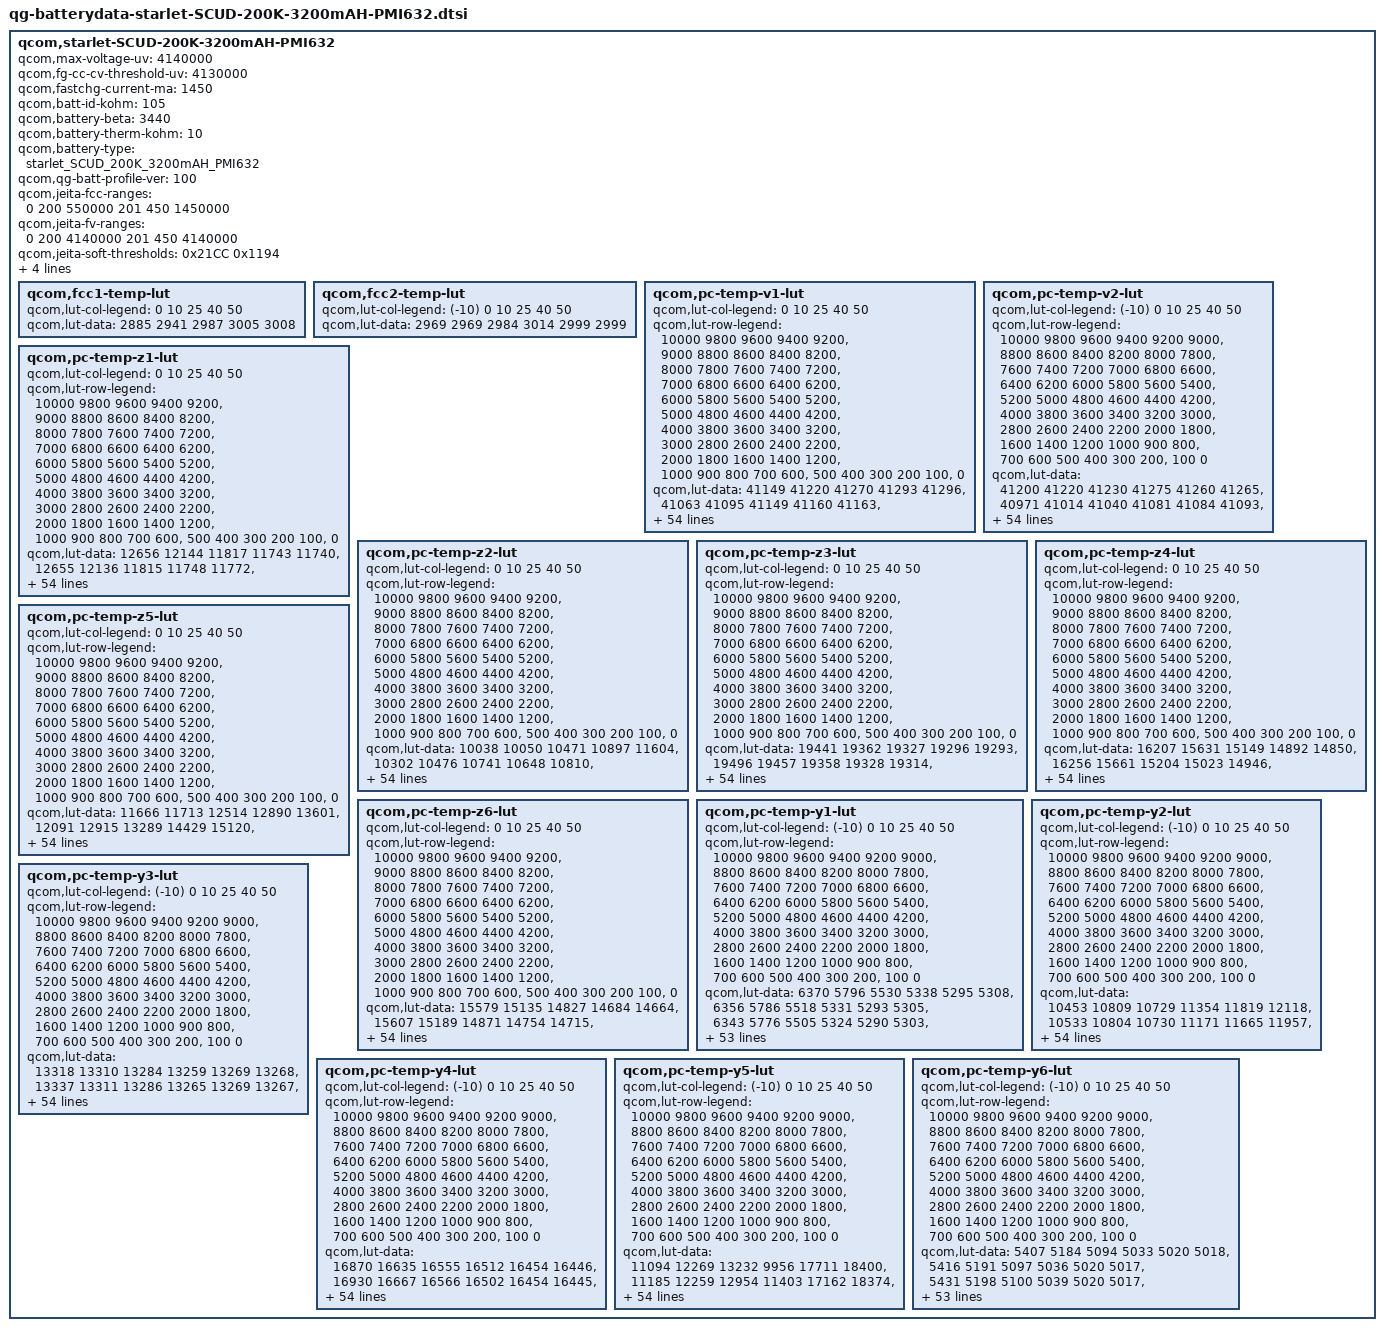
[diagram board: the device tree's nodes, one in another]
qcom,starlet-SCUD-200K-3200mAH-PMI632 {
	qcom,max-voltage-uv = <4140000>;
	qcom,fg-cc-cv-threshold-uv = <4130000>;
	qcom,fastchg-current-ma = <1450>;
	qcom,batt-id-kohm = <105>; // 220K on board in parallel with 200K on pack = 104.76K
	qcom,battery-beta = <3440>;
	qcom,battery-therm-kohm = <10>;
	qcom,battery-type = "starlet_SCUD_200K_3200mAH_PMI632";
	qcom,qg-batt-profile-ver = <100>;

	qcom,jeita-fcc-ranges = <0  200  550000
				201 450  1450000>;

	qcom,jeita-fv-ranges = <0   200  4140000
				201 450  4140000>;

	/*
	 * JEITA ADC values are calculated as follows, assuming
	 * a 30K pull-up. r_therm comes from the NTCG063JF103FTB
	 * thermistor datasheet.
	 *   v_adc = v_pull / ((r_pullup + r_therm) * r_therm)
	 *   v_adc = 1.875 / ((30K + r_therm) * r_therm)
	 *   adc_code = v_adc * v_fullscale / v_ref
	 *   adc_code = 10000 * v_adc * 2.89 / 1.875
	 *
	 * NOTE: to compensate for high IR drop with the starlet
	 * battery flex and connector, r_therm values are used
	 * that correspond roughly to 1.5C lower than the desired
	 * temperatures. Ie. the ADC under-reports temperatures,
	 * so we use lower thresholds to compensate.
	 */
	/* COOL = 20 degC, WARM = 43 degC */
	qcom,jeita-soft-thresholds = <0x21CC 0x1194>; /* 18.5 degC, 41.5 degC */
	/* COLD = 0 degC, HOT = 45 degC*/
	qcom,jeita-hard-thresholds = <0x379A 0x1096>; /* -1.5 degC, 43.5 degC */
	/* COOL hys = 23 degC, WARM hys = 42 degC */
	qcom,jeita-soft-hys-thresholds = <0x1F20 0x1218>; /* 21.5 degC, 40.5 degC */
	qcom,jeita-soft-fcc-ua = <550000 550000>;
	qcom,jeita-soft-fv-uv = <4140000 4140000>;


	qcom,fcc1-temp-lut {
		qcom,lut-col-legend = <0 10 25 40 50>;
		qcom,lut-data = <2885 2941 2987 3005 3008>;
	};

	qcom,fcc2-temp-lut {
		qcom,lut-col-legend = <(-10) 0 10 25 40 50>;
		qcom,lut-data = <2969 2969 2984 3014 2999 2999>;
	};

	qcom,pc-temp-v1-lut {
		qcom,lut-col-legend = <0 10 25 40 50>;
		qcom,lut-row-legend = <10000 9800 9600 9400 9200>,
			<9000 8800 8600 8400 8200>,
			<8000 7800 7600 7400 7200>,
			<7000 6800 6600 6400 6200>,
			<6000 5800 5600 5400 5200>,
			<5000 4800 4600 4400 4200>,
			<4000 3800 3600 3400 3200>,
			<3000 2800 2600 2400 2200>,
			<2000 1800 1600 1400 1200>,
			<1000 900 800 700 600>,
			<500 400 300 200 100>,
			<0>;
		qcom,lut-data = <41149 41220 41270 41293 41296>,
			<41063 41095 41149 41160 41163>,
			<41001 41013 41043 41058 41062>,
			<40945 40960 40974 40986 40990>,
			<40888 40911 40929 40939 40943>,
			<40833 40856 40877 40891 40897>,
			<40756 40792 40813 40825 40832>,
			<40616 40697 40729 40742 40752>,
			<40433 40533 40599 40624 40636>,
			<40239 40333 40405 40433 40442>,
			<40015 40121 40193 40214 40219>,
			<39803 39892 39968 39996 40003>,
			<39624 39691 39747 39772 39782>,
			<39460 39523 39568 39585 39595>,
			<39312 39372 39415 39428 39437>,
			<39184 39234 39273 39284 39291>,
			<39055 39109 39142 39148 39153>,
			<38912 38974 39011 39019 39021>,
			<38758 38823 38866 38876 38876>,
			<38594 38660 38709 38720 38720>,
			<38418 38483 38529 38542 38542>,
			<38229 38292 38310 38313 38318>,
			<38034 38074 38062 38050 38062>,
			<37830 37797 37794 37802 37820>,
			<37613 37497 37505 37560 37587>,
			<37366 37252 37268 37344 37375>,
			<37108 37043 37103 37170 37198>,
			<36902 36872 36965 37018 37040>,
			<36730 36743 36836 36878 36896>,
			<36588 36636 36718 36747 36763>,
			<36478 36535 36605 36625 36639>,
			<36389 36441 36491 36509 36521>,
			<36302 36348 36379 36397 36410>,
			<36216 36250 36272 36285 36297>,
			<36129 36147 36167 36175 36185>,
			<36033 36041 36059 36061 36067>,
			<35930 35933 35948 35942 35941>,
			<35814 35814 35829 35817 35806>,
			<35687 35673 35684 35668 35651>,
			<35543 35506 35509 35490 35474>,
			<35363 35315 35311 35289 35275>,
			<35126 35083 35082 35057 35041>,
			<34889 34840 34836 34807 34788>,
			<34662 34603 34588 34559 34541>,
			<34456 34391 34367 34336 34322>,
			<34299 34222 34184 34149 34140>,
			<34231 34152 34105 34066 34057>,
			<34166 34083 34030 33984 33975>,
			<34099 34011 33952 33900 33888>,
			<34008 33916 33852 33799 33780>,
			<33852 33735 33678 33585 33533>,
			<33503 33322 33283 33163 33107>,
			<32960 32755 32742 32623 32569>,
			<32273 32030 32047 31941 31890>,
			<31357 31048 31114 31025 30986>,
			<30000 30000 30000 30000 30000>;
	};

	qcom,pc-temp-v2-lut {
		qcom,lut-col-legend = <(-10) 0 10 25 40 50>;
		qcom,lut-row-legend = <10000 9800 9600 9400 9200 9000>,
			<8800 8600 8400 8200 8000 7800>,
			<7600 7400 7200 7000 6800 6600>,
			<6400 6200 6000 5800 5600 5400>,
			<5200 5000 4800 4600 4400 4200>,
			<4000 3800 3600 3400 3200 3000>,
			<2800 2600 2400 2200 2000 1800>,
			<1600 1400 1200 1000 900 800>,
			<700 600 500 400 300 200>,
			<100 0>;
		qcom,lut-data = <41200 41220 41230 41275 41260 41265>,
			<40971 41014 41040 41081 41084 41093>,
			<40799 40858 40896 40935 40949 40961>,
			<40711 40778 40818 40857 40872 40884>,
			<40665 40737 40777 40814 40828 40840>,
			<40619 40694 40733 40768 40780 40791>,
			<40556 40631 40668 40707 40709 40719>,
			<40480 40549 40584 40632 40618 40628>,
			<40370 40429 40462 40514 40488 40497>,
			<40197 40232 40264 40325 40287 40295>,
			<39991 40009 40043 40114 40067 40074>,
			<39754 39792 39821 39891 39849 39855>,
			<39491 39573 39597 39665 39631 39636>,
			<39264 39400 39412 39477 39450 39456>,
			<39069 39274 39258 39314 39297 39304>,
			<38888 39142 39117 39165 39154 39162>,
			<38720 38967 38988 39032 39020 39026>,
			<38561 38760 38861 38902 38889 38893>,
			<38394 38547 38690 38751 38739 38744>,
			<38215 38321 38444 38581 38574 38580>,
			<38031 38094 38184 38384 38386 38395>,
			<37838 37882 37943 38131 38148 38159>,
			<37639 37677 37709 37855 37882 37896>,
			<37439 37477 37492 37610 37635 37653>,
			<37234 37275 37289 37383 37397 37418>,
			<37037 37083 37100 37179 37185 37209>,
			<36861 36910 36928 36998 37007 37032>,
			<36699 36751 36770 36835 36850 36875>,
			<36553 36606 36629 36691 36709 36734>,
			<36423 36476 36503 36563 36582 36607>,
			<36303 36357 36386 36443 36465 36488>,
			<36188 36241 36274 36327 36352 36374>,
			<36078 36132 36166 36215 36243 36263>,
			<35967 36023 36058 36105 36130 36147>,
			<35853 35912 35948 35996 36012 36026>,
			<35734 35800 35835 35881 35886 35893>,
			<35608 35685 35717 35761 35744 35740>,
			<35473 35568 35592 35632 35592 35571>,
			<35321 35434 35449 35480 35430 35403>,
			<35143 35276 35286 35306 35259 35234>,
			<34942 35091 35097 35112 35070 35049>,
			<34719 34869 34867 34890 34850 34832>,
			<34470 34601 34606 34645 34608 34594>,
			<34263 34347 34352 34375 34347 34337>,
			<34078 34115 34129 34154 34135 34128>,
			<33873 33928 33950 33981 33974 33969>,
			<33749 33832 33858 33899 33894 33888>,
			<33604 33715 33753 33803 33806 33803>,
			<33414 33587 33641 33704 33706 33706>,
			<33194 33426 33495 33583 33582 33572>,
			<32922 33203 33266 33359 33323 33289>,
			<32509 32832 32855 32930 32871 32827>,
			<31950 32297 32282 32356 32299 32258>,
			<31282 31639 31570 31648 31603 31562>,
			<30500 30842 30655 30776 30724 30693>,
			<29445 29818 29444 29679 29654 29640>;
	};

	qcom,pc-temp-z1-lut {
		qcom,lut-col-legend = <0 10 25 40 50>;
		qcom,lut-row-legend = <10000 9800 9600 9400 9200>,
			<9000 8800 8600 8400 8200>,
			<8000 7800 7600 7400 7200>,
			<7000 6800 6600 6400 6200>,
			<6000 5800 5600 5400 5200>,
			<5000 4800 4600 4400 4200>,
			<4000 3800 3600 3400 3200>,
			<3000 2800 2600 2400 2200>,
			<2000 1800 1600 1400 1200>,
			<1000 900 800 700 600>,
			<500 400 300 200 100>,
			<0>;
		qcom,lut-data = <12656 12144 11817 11743 11740>,
			<12655 12136 11815 11748 11772>,
			<12649 12133 11817 11762 11784>,
			<12640 12123 11816 11766 11788>,
			<12623 12107 11810 11765 11789>,
			<12593 12091 11805 11764 11789>,
			<12568 12074 11799 11762 11788>,
			<12549 12059 11794 11759 11785>,
			<12532 12046 11790 11758 11784>,
			<12513 12035 11786 11760 11787>,
			<12495 12025 11784 11761 11790>,
			<12478 12014 11783 11763 11792>,
			<12462 12007 11783 11764 11793>,
			<12447 12003 11783 11764 11793>,
			<12434 11999 11782 11763 11793>,
			<12420 11997 11781 11763 11793>,
			<12411 11994 11780 11763 11793>,
			<12409 11992 11779 11763 11792>,
			<12408 11991 11779 11763 11792>,
			<12407 11990 11780 11763 11793>,
			<12408 11991 11781 11764 11794>,
			<12410 11995 11781 11765 11795>,
			<12412 11997 11782 11766 11796>,
			<12415 11998 11783 11767 11797>,
			<12418 11999 11784 11768 11799>,
			<12420 12000 11785 11770 11800>,
			<12424 12000 11787 11771 11802>,
			<12426 12001 11788 11773 11803>,
			<12428 12003 11790 11774 11804>,
			<12430 12005 11793 11776 11805>,
			<12432 12008 11795 11778 11807>,
			<12434 12013 11798 11779 11808>,
			<12438 12018 11802 11781 11809>,
			<12447 12023 11806 11782 11809>,
			<12458 12030 11810 11784 11810>,
			<12469 12038 11814 11786 11812>,
			<12482 12048 11819 11789 11813>,
			<12498 12060 11825 11792 11816>,
			<12522 12077 11832 11796 11819>,
			<12554 12100 11842 11802 11824>,
			<12587 12124 11854 11809 11829>,
			<12624 12148 11867 11816 11834>,
			<12664 12175 11883 11824 11841>,
			<12710 12206 11904 11836 11850>,
			<12764 12249 11929 11852 11860>,
			<12782 12266 11953 11868 11871>,
			<12790 12268 11963 11876 11877>,
			<12781 12282 11972 11884 11885>,
			<12777 12275 11978 11893 11892>,
			<12787 12290 11987 11902 11899>,
			<12802 12306 11999 11912 11909>,
			<12830 12319 12013 11923 11919>,
			<12842 12333 12029 11937 11932>,
			<12864 12349 12052 11955 11944>,
			<12864 12349 12052 11955 11944>,
			<12864 12349 12052 11955 11944>;
	};

	qcom,pc-temp-z2-lut {
		qcom,lut-col-legend = <0 10 25 40 50>;
		qcom,lut-row-legend = <10000 9800 9600 9400 9200>,
			<9000 8800 8600 8400 8200>,
			<8000 7800 7600 7400 7200>,
			<7000 6800 6600 6400 6200>,
			<6000 5800 5600 5400 5200>,
			<5000 4800 4600 4400 4200>,
			<4000 3800 3600 3400 3200>,
			<3000 2800 2600 2400 2200>,
			<2000 1800 1600 1400 1200>,
			<1000 900 800 700 600>,
			<500 400 300 200 100>,
			<0>;
		qcom,lut-data = <10038 10050 10471 10897 11604>,
			<10302 10476 10741 10648 10810>,
			<10407 10625 10868 10714 10801>,
			<10470 10665 10924 10773 10848>,
			<10513 10680 10956 10924 10957>,
			<10546 10692 10968 11051 11052>,
			<10556 10719 10981 11116 11071>,
			<10512 10726 10995 11205 11065>,
			<10456 10659 10957 11208 11062>,
			<10466 10571 10825 11075 11056>,
			<10549 10513 10731 10938 11028>,
			<10605 10469 10708 10842 10913>,
			<10535 10458 10684 10744 10742>,
			<10411 10481 10623 10715 10700>,
			<10377 10521 10485 10669 10745>,
			<10399 10554 10412 10648 10805>,
			<10431 10586 10460 10709 10863>,
			<10461 10622 10532 10788 10922>,
			<10496 10669 10565 10806 10947>,
			<10523 10714 10580 10802 10952>,
			<10542 10749 10617 10799 10964>,
			<10558 10786 10873 11029 11191>,
			<10575 10807 11174 11446 11595>,
			<10592 10810 11211 11534 11650>,
			<10610 10809 11187 11420 11268>,
			<10635 10805 11165 11273 10950>,
			<10659 10796 11149 11140 10915>,
			<10666 10790 11127 10996 10896>,
			<10666 10797 11047 10841 10833>,
			<10666 10816 10847 10658 10611>,
			<10668 10841 10731 10524 10455>,
			<10675 10885 10728 10458 10479>,
			<10688 10916 10733 10414 10542>,
			<10759 10847 10665 10418 10609>,
			<10838 10704 10454 10499 10687>,
			<10829 10661 10338 10601 10777>,
			<10743 10705 10397 10712 10905>,
			<10671 10755 10526 10826 11034>,
			<10641 10783 10705 10873 11060>,
			<10620 10816 10996 10899 11046>,
			<10619 10834 11149 10910 11026>,
			<10637 10836 11117 10856 10998>,
			<10642 10826 11060 10770 10953>,
			<10621 10789 11007 10718 10877>,
			<10705 10779 10728 10669 10777>,
			<10649 10719 10395 10559 10626>,
			<10585 10620 10482 10500 10632>,
			<10505 10527 10448 10457 10580>,
			<10410 10450 10373 10434 10598>,
			<10360 10367 10544 10465 10614>,
			<10308 10325 10307 10225 10336>,
			<10272 10192 9897 10058 10195>,
			<10148 10010 9772 9982 10161>,
			<9956 9692 9664 9943 10270>,
			<9956 9692 9664 9943 10270>,
			<9956 9692 9664 9943 10270>;
	};

	qcom,pc-temp-z3-lut {
		qcom,lut-col-legend = <0 10 25 40 50>;
		qcom,lut-row-legend = <10000 9800 9600 9400 9200>,
			<9000 8800 8600 8400 8200>,
			<8000 7800 7600 7400 7200>,
			<7000 6800 6600 6400 6200>,
			<6000 5800 5600 5400 5200>,
			<5000 4800 4600 4400 4200>,
			<4000 3800 3600 3400 3200>,
			<3000 2800 2600 2400 2200>,
			<2000 1800 1600 1400 1200>,
			<1000 900 800 700 600>,
			<500 400 300 200 100>,
			<0>;
		qcom,lut-data = <19441 19362 19327 19296 19293>,
			<19496 19457 19358 19328 19314>,
			<19517 19480 19387 19336 19320>,
			<19531 19475 19391 19340 19323>,
			<19546 19470 19390 19341 19323>,
			<19560 19473 19391 19343 19324>,
			<19578 19487 19401 19352 19328>,
			<19616 19507 19419 19368 19335>,
			<19662 19547 19435 19379 19343>,
			<19696 19576 19451 19389 19357>,
			<19730 19576 19457 19394 19367>,
			<19746 19569 19455 19390 19361>,
			<19713 19557 19450 19379 19347>,
			<19648 19526 19430 19368 19334>,
			<19608 19485 19384 19351 19322>,
			<19583 19454 19352 19335 19314>,
			<19564 19427 19340 19322 19311>,
			<19547 19417 19333 19312 19309>,
			<19528 19418 19333 19310 19308>,
			<19522 19421 19334 19311 19310>,
			<19524 19428 19338 19314 19314>,
			<19529 19446 19368 19331 19324>,
			<19537 19466 19406 19357 19338>,
			<19558 19491 19412 19362 19340>,
			<19582 19514 19411 19357 19337>,
			<19615 19517 19409 19350 19334>,
			<19649 19513 19400 19341 19335>,
			<19656 19506 19383 19331 19338>,
			<19648 19492 19363 19331 19339>,
			<19634 19469 19337 19342 19337>,
			<19617 19443 19325 19350 19335>,
			<19592 19407 19355 19348 19329>,
			<19562 19379 19396 19342 19318>,
			<19515 19379 19395 19335 19312>,
			<19474 19397 19362 19325 19307>,
			<19474 19407 19341 19319 19304>,
			<19498 19414 19340 19318 19308>,
			<19526 19424 19339 19319 19316>,
			<19549 19438 19342 19319 19316>,
			<19571 19461 19358 19319 19307>,
			<19591 19478 19371 19319 19302>,
			<19612 19487 19380 19319 19302>,
			<19616 19491 19385 19319 19304>,
			<19595 19488 19389 19323 19306>,
			<19514 19454 19370 19326 19307>,
			<19507 19453 19359 19331 19313>,
			<19521 19464 19375 19335 19316>,
			<19532 19472 19381 19340 19318>,
			<19541 19474 19381 19338 19317>,
			<19562 19478 19393 19336 19313>,
			<19567 19475 19393 19336 19325>,
			<19572 19533 19402 19360 19330>,
			<19641 19556 19399 19363 19334>,
			<19662 19535 19393 19319 19298>,
			<19662 19535 19393 19319 19298>,
			<19662 19535 19393 19319 19298>;
	};

	qcom,pc-temp-z4-lut {
		qcom,lut-col-legend = <0 10 25 40 50>;
		qcom,lut-row-legend = <10000 9800 9600 9400 9200>,
			<9000 8800 8600 8400 8200>,
			<8000 7800 7600 7400 7200>,
			<7000 6800 6600 6400 6200>,
			<6000 5800 5600 5400 5200>,
			<5000 4800 4600 4400 4200>,
			<4000 3800 3600 3400 3200>,
			<3000 2800 2600 2400 2200>,
			<2000 1800 1600 1400 1200>,
			<1000 900 800 700 600>,
			<500 400 300 200 100>,
			<0>;
		qcom,lut-data = <16207 15631 15149 14892 14850>,
			<16256 15661 15204 15023 14946>,
			<16130 15640 15201 15008 14927>,
			<15972 15542 15178 14990 14909>,
			<15876 15438 15128 14967 14892>,
			<15797 15380 15083 14940 14875>,
			<15717 15335 15051 14917 14859>,
			<15632 15279 15019 14893 14842>,
			<15543 15206 14979 14865 14821>,
			<15432 15133 14933 14832 14791>,
			<15289 15072 14889 14801 14764>,
			<15196 15018 14840 14774 14746>,
			<15174 14979 14805 14750 14732>,
			<15161 14953 14804 14740 14722>,
			<15137 14934 14816 14736 14714>,
			<15089 14919 14823 14731 14707>,
			<15043 14907 14811 14725 14696>,
			<15019 14892 14791 14716 14682>,
			<15001 14869 14773 14707 14672>,
			<14982 14843 14756 14694 14662>,
			<14962 14818 14746 14687 14657>,
			<14940 14792 14746 14705 14679>,
			<14915 14781 14754 14747 14729>,
			<14882 14823 14793 14789 14769>,
			<14865 14899 14891 14840 14807>,
			<14881 14948 14941 14870 14828>,
			<14916 14982 14937 14868 14818>,
			<14947 14999 14931 14861 14795>,
			<14979 14996 14931 14849 14772>,
			<15000 14990 14935 14812 14747>,
			<14999 14989 14935 14775 14727>,
			<14994 14992 14876 14750 14713>,
			<14992 14994 14794 14730 14701>,
			<15002 14973 14778 14719 14694>,
			<15016 14913 14777 14711 14688>,
			<15004 14870 14776 14706 14685>,
			<14946 14827 14763 14706 14687>,
			<14902 14796 14748 14706 14691>,
			<14891 14798 14750 14712 14699>,
			<14884 14812 14775 14737 14718>,
			<14889 14832 14798 14761 14734>,
			<14936 14874 14813 14775 14742>,
			<14961 14900 14823 14782 14746>,
			<14966 14902 14827 14782 14746>,
			<14916 14873 14819 14765 14736>,
			<14905 14841 14807 14735 14708>,
			<14892 14828 14784 14722 14694>,
			<14873 14809 14765 14705 14679>,
			<14860 14798 14750 14696 14669>,
			<14857 14811 14746 14699 14675>,
			<14919 14884 14796 14736 14687>,
			<15014 14912 14836 14726 14689>,
			<15026 14932 14856 14729 14688>,
			<15059 14990 14840 14727 14674>,
			<15059 14990 14840 14727 14674>,
			<15059 14990 14840 14727 14674>;
	};

	qcom,pc-temp-z5-lut {
		qcom,lut-col-legend = <0 10 25 40 50>;
		qcom,lut-row-legend = <10000 9800 9600 9400 9200>,
			<9000 8800 8600 8400 8200>,
			<8000 7800 7600 7400 7200>,
			<7000 6800 6600 6400 6200>,
			<6000 5800 5600 5400 5200>,
			<5000 4800 4600 4400 4200>,
			<4000 3800 3600 3400 3200>,
			<3000 2800 2600 2400 2200>,
			<2000 1800 1600 1400 1200>,
			<1000 900 800 700 600>,
			<500 400 300 200 100>,
			<0>;
		qcom,lut-data = <11666 11713 12514 12890 13601>,
			<12091 12915 13289 14429 15120>,
			<12332 13338 14199 14944 15654>,
			<12517 13434 14541 15273 15970>,
			<12678 13507 14679 15591 16268>,
			<12811 13601 14843 15842 16514>,
			<12963 13767 15101 16191 16662>,
			<13181 14046 15440 16776 16777>,
			<13455 14594 15844 17323 17129>,
			<13829 15088 16313 17964 18681>,
			<14415 15305 16829 18503 19906>,
			<14748 15454 17539 18894 19598>,
			<14533 15488 18127 19194 18747>,
			<14148 15212 17576 18968 17962>,
			<14054 14822 15478 17675 17094>,
			<14240 14595 14349 16494 16575>,
			<14407 14429 14347 16017 16765>,
			<14454 14385 14370 15672 17356>,
			<14598 14747 14504 15689 18266>,
			<14791 15540 15062 16508 20249>,
			<15172 16784 16374 17999 22799>,
			<15807 19225 25622 24253 26287>,
			<16813 22753 37131 33687 30024>,
			<18782 30588 38326 34996 30129>,
			<21655 39201 34798 28197 24131>,
			<29056 40341 30466 21358 18454>,
			<38601 36878 25724 17777 16445>,
			<40853 32515 20968 15181 15134>,
			<38489 28261 17590 14660 14855>,
			<34962 23728 14743 14626 15291>,
			<30991 20078 13616 14613 15653>,
			<26046 16806 14603 15012 15730>,
			<21862 14695 15973 15817 15950>,
			<18020 14308 15999 16355 16288>,
			<15279 14601 15185 16799 16823>,
			<15064 15039 14734 17071 17495>,
			<15712 16022 15310 17499 18571>,
			<16630 17282 16272 18122 19718>,
			<18280 18902 16867 18048 19547>,
			<20353 21232 17338 16729 16998>,
			<21415 22110 17586 15486 14949>,
			<22002 20711 17248 14894 14531>,
			<21994 19336 16837 14564 14319>,
			<20637 18671 16444 14487 14214>,
			<20777 18716 15712 14844 14459>,
			<20488 19718 15643 15931 15722>,
			<20975 20378 16844 16838 16821>,
			<21811 21818 18178 18550 18255>,
			<22409 23189 19647 20087 20122>,
			<23812 23000 22111 19453 18266>,
			<21194 17885 17036 14981 16106>,
			<17082 16479 14399 15824 16108>,
			<16955 15699 13536 15600 16186>,
			<15704 14044 13585 14004 15045>,
			<15704 14044 13585 14004 15045>,
			<15704 14044 13585 14004 15045>;
	};

	qcom,pc-temp-z6-lut {
		qcom,lut-col-legend = <0 10 25 40 50>;
		qcom,lut-row-legend = <10000 9800 9600 9400 9200>,
			<9000 8800 8600 8400 8200>,
			<8000 7800 7600 7400 7200>,
			<7000 6800 6600 6400 6200>,
			<6000 5800 5600 5400 5200>,
			<5000 4800 4600 4400 4200>,
			<4000 3800 3600 3400 3200>,
			<3000 2800 2600 2400 2200>,
			<2000 1800 1600 1400 1200>,
			<1000 900 800 700 600>,
			<500 400 300 200 100>,
			<0>;
		qcom,lut-data = <15579 15135 14827 14684 14664>,
			<15607 15189 14871 14754 14715>,
			<15547 15187 14881 14755 14714>,
			<15472 15137 14873 14754 14712>,
			<15426 15083 14848 14743 14705>,
			<15387 15057 14829 14733 14698>,
			<15356 15039 14821 14729 14693>,
			<15333 15022 14814 14726 14690>,
			<15311 15007 14805 14721 14686>,
			<15280 14990 14793 14713 14681>,
			<15239 14967 14779 14702 14676>,
			<15197 14938 14761 14689 14666>,
			<15158 14910 14742 14674 14652>,
			<15120 14880 14724 14661 14640>,
			<15085 14852 14707 14650 14631>,
			<15049 14829 14693 14639 14622>,
			<15020 14810 14679 14629 14614>,
			<14998 14796 14668 14620 14607>,
			<14980 14783 14660 14614 14603>,
			<14968 14774 14653 14610 14600>,
			<14959 14772 14650 14608 14599>,
			<14953 14771 14662 14623 14613>,
			<14951 14772 14686 14655 14642>,
			<14950 14800 14715 14678 14662>,
			<14950 14848 14755 14697 14677>,
			<14970 14870 14773 14706 14685>,
			<15006 14881 14767 14704 14682>,
			<15023 14886 14755 14696 14676>,
			<15031 14879 14746 14689 14668>,
			<15035 14865 14737 14680 14658>,
			<15030 14851 14728 14671 14648>,
			<15013 14837 14719 14660 14637>,
			<14998 14824 14710 14649 14627>,
			<14982 14811 14699 14639 14620>,
			<14969 14799 14684 14629 14614>,
			<14961 14788 14672 14624 14611>,
			<14956 14777 14664 14624 14613>,
			<14953 14769 14659 14624 14618>,
			<14961 14776 14662 14626 14623>,
			<14980 14798 14682 14638 14628>,
			<15005 14823 14702 14650 14632>,
			<15047 14852 14715 14657 14637>,
			<15071 14873 14726 14662 14641>,
			<15080 14885 14735 14668 14645>,
			<15047 14867 14727 14663 14642>,
			<15051 14866 14723 14657 14635>,
			<15057 14870 14725 14656 14633>,
			<15059 14871 14723 14653 14628>,
			<15062 14871 14720 14650 14625>,
			<15080 14885 14729 14653 14627>,
			<15118 14924 14757 14674 14644>,
			<15176 14976 14787 14689 14652>,
			<15226 15007 14802 14698 14657>,
			<15267 15036 14806 14681 14636>,
			<15267 15036 14806 14681 14636>,
			<15267 15036 14806 14681 14636>;
	};

	qcom,pc-temp-y1-lut {
		qcom,lut-col-legend = <(-10) 0 10 25 40 50>;
		qcom,lut-row-legend = <10000 9800 9600 9400 9200 9000>,
			<8800 8600 8400 8200 8000 7800>,
			<7600 7400 7200 7000 6800 6600>,
			<6400 6200 6000 5800 5600 5400>,
			<5200 5000 4800 4600 4400 4200>,
			<4000 3800 3600 3400 3200 3000>,
			<2800 2600 2400 2200 2000 1800>,
			<1600 1400 1200 1000 900 800>,
			<700 600 500 400 300 200>,
			<100 0>;
		qcom,lut-data = <6370 5796 5530 5338 5295 5308>,
			<6356 5786 5518 5331 5293 5305>,
			<6343 5776 5505 5324 5290 5303>,
			<6330 5765 5493 5317 5288 5300>,
			<6318 5756 5482 5311 5285 5298>,
			<6306 5747 5474 5307 5284 5296>,
			<6295 5739 5467 5304 5283 5294>,
			<6284 5732 5461 5302 5282 5293>,
			<6274 5725 5454 5300 5281 5292>,
			<6264 5719 5446 5297 5279 5293>,
			<6256 5713 5440 5295 5278 5294>,
			<6249 5706 5436 5294 5279 5293>,
			<6242 5700 5433 5294 5279 5293>,
			<6239 5697 5431 5293 5279 5293>,
			<6242 5696 5429 5292 5279 5293>,
			<6244 5696 5429 5291 5278 5292>,
			<6237 5695 5429 5292 5279 5293>,
			<6226 5694 5429 5293 5279 5293>,
			<6223 5694 5429 5293 5279 5293>,
			<6229 5695 5428 5293 5279 5293>,
			<6234 5695 5428 5293 5279 5293>,
			<6235 5694 5428 5293 5279 5294>,
			<6234 5691 5429 5294 5279 5295>,
			<6233 5690 5429 5295 5280 5295>,
			<6226 5689 5429 5295 5280 5293>,
			<6219 5689 5429 5296 5280 5292>,
			<6222 5689 5427 5296 5281 5293>,
			<6232 5692 5425 5296 5281 5294>,
			<6237 5694 5425 5296 5281 5294>,
			<6243 5695 5427 5295 5282 5295>,
			<6249 5697 5430 5296 5282 5296>,
			<6254 5700 5432 5298 5283 5296>,
			<6260 5705 5435 5300 5283 5297>,
			<6265 5711 5439 5301 5284 5297>,
			<6269 5718 5442 5302 5284 5298>,
			<6273 5728 5446 5303 5285 5299>,
			<6277 5737 5452 5306 5287 5301>,
			<6289 5747 5461 5311 5288 5303>,
			<6302 5758 5470 5314 5290 5304>,
			<6321 5771 5481 5318 5293 5305>,
			<6340 5785 5494 5323 5296 5307>,
			<6343 5801 5509 5332 5300 5309>,
			<6338 5818 5524 5342 5306 5313>,
			<6336 5833 5539 5355 5313 5318>,
			<6334 5846 5564 5373 5320 5324>,
			<6352 5858 5578 5389 5331 5330>,
			<6409 5864 5587 5401 5335 5335>,
			<6445 5850 5603 5414 5346 5340>,
			<6487 5858 5603 5424 5353 5344>,
			<6552 5864 5611 5435 5361 5352>,
			<6576 5888 5610 5444 5371 5357>,
			<6639 5913 5606 5454 5377 5363>,
			<6665 5967 5626 5466 5386 5371>,
			<6747 5996 5634 5474 5397 5380>,
			<6747 5996 5634 5474 5397 5380>,
			<6747 5996 5634 5474 5397 5380>;
	};

	qcom,pc-temp-y2-lut {
		qcom,lut-col-legend = <(-10) 0 10 25 40 50>;
		qcom,lut-row-legend = <10000 9800 9600 9400 9200 9000>,
			<8800 8600 8400 8200 8000 7800>,
			<7600 7400 7200 7000 6800 6600>,
			<6400 6200 6000 5800 5600 5400>,
			<5200 5000 4800 4600 4400 4200>,
			<4000 3800 3600 3400 3200 3000>,
			<2800 2600 2400 2200 2000 1800>,
			<1600 1400 1200 1000 900 800>,
			<700 600 500 400 300 200>,
			<100 0>;
		qcom,lut-data = <10453 10809 10729 11354 11819 12118>,
			<10533 10804 10730 11171 11665 11957>,
			<10609 10811 10746 11036 11507 11764>,
			<10683 10828 10774 10945 11357 11570>,
			<10751 10853 10811 10893 11226 11404>,
			<10814 10883 10857 10878 11128 11296>,
			<10875 10925 10913 10918 11049 11236>,
			<10930 10982 10978 10985 10989 11188>,
			<10969 11047 11042 11023 10970 11147>,
			<10997 11131 11104 11053 10966 11106>,
			<11023 11208 11174 11093 10973 11087>,
			<11052 11269 11259 11182 11084 11099>,
			<11081 11325 11357 11294 11265 11130>,
			<11108 11341 11459 11372 11349 11195>,
			<11136 11320 11577 11433 11392 11362>,
			<11156 11299 11663 11482 11428 11464>,
			<11163 11305 11701 11515 11466 11384>,
			<11169 11319 11728 11547 11502 11259>,
			<11177 11331 11716 11628 11537 11277>,
			<11197 11340 11605 11789 11585 11500>,
			<11220 11351 11519 11866 11646 11655>,
			<11237 11370 11518 11783 11752 11660>,
			<11254 11398 11531 11654 11861 11646>,
			<11271 11428 11545 11591 11847 11622>,
			<11294 11464 11559 11549 11668 11583>,
			<11318 11502 11578 11515 11551 11562>,
			<11347 11542 11634 11481 11591 11600>,
			<11381 11590 11725 11459 11659 11678>,
			<11402 11627 11801 11559 11698 11768>,
			<11414 11659 11868 11884 11763 11945>,
			<11423 11683 11918 12060 11855 12106>,
			<11427 11698 11951 12082 12098 12229>,
			<11429 11709 11975 12098 12391 12327>,
			<11429 11712 11975 12131 12437 12314>,
			<11417 11698 11930 12179 12380 12142>,
			<11395 11673 11881 12197 12289 11973>,
			<11360 11650 11867 12160 12035 11868>,
			<11294 11625 11860 12099 11719 11781>,
			<11211 11592 11840 12034 11647 11721>,
			<11118 11548 11774 11923 11648 11662>,
			<10980 11479 11667 11772 11648 11633>,
			<10600 11345 11509 11540 11640 11639>,
			<9856 11054 11291 11363 11626 11630>,
			<9685 10536 11073 11199 11405 11517>,
			<9661 9906 10696 10978 11233 11370>,
			<9659 9705 10183 10794 11056 11213>,
			<9657 9675 10065 10842 11021 11068>,
			<9657 9664 9911 10519 10844 11004>,
			<9656 9660 9794 10594 10771 11012>,
			<9656 9661 9717 10618 10913 10884>,
			<9656 9660 9685 10346 10631 10898>,
			<9655 9659 9671 10124 10584 10786>,
			<9655 9659 9665 10018 10527 10760>,
			<9656 9660 9669 9955 10629 10755>,
			<9656 9660 9669 9955 10629 10755>,
			<9656 9660 9669 9955 10629 10755>;
	};

	qcom,pc-temp-y3-lut {
		qcom,lut-col-legend = <(-10) 0 10 25 40 50>;
		qcom,lut-row-legend = <10000 9800 9600 9400 9200 9000>,
			<8800 8600 8400 8200 8000 7800>,
			<7600 7400 7200 7000 6800 6600>,
			<6400 6200 6000 5800 5600 5400>,
			<5200 5000 4800 4600 4400 4200>,
			<4000 3800 3600 3400 3200 3000>,
			<2800 2600 2400 2200 2000 1800>,
			<1600 1400 1200 1000 900 800>,
			<700 600 500 400 300 200>,
			<100 0>;
		qcom,lut-data = <13318 13310 13284 13259 13269 13268>,
			<13337 13311 13286 13265 13269 13267>,
			<13356 13315 13289 13271 13269 13267>,
			<13373 13319 13292 13276 13270 13267>,
			<13385 13323 13295 13281 13271 13268>,
			<13389 13325 13296 13285 13272 13270>,
			<13386 13326 13297 13287 13274 13272>,
			<13379 13328 13298 13289 13277 13274>,
			<13380 13327 13300 13290 13278 13276>,
			<13397 13319 13307 13290 13279 13277>,
			<13410 13314 13312 13291 13280 13279>,
			<13407 13317 13313 13295 13284 13279>,
			<13400 13323 13314 13300 13289 13279>,
			<13392 13331 13315 13300 13290 13280>,
			<13381 13346 13317 13296 13288 13284>,
			<13370 13356 13319 13293 13286 13286>,
			<13360 13355 13324 13301 13289 13284>,
			<13352 13350 13332 13312 13294 13281>,
			<13348 13345 13333 13315 13297 13281>,
			<13347 13338 13323 13315 13299 13287>,
			<13346 13331 13312 13315 13300 13290>,
			<13344 13323 13303 13306 13296 13287>,
			<13341 13316 13296 13292 13288 13281>,
			<13340 13312 13292 13285 13281 13276>,
			<13340 13309 13288 13279 13274 13272>,
			<13341 13308 13286 13277 13270 13270>,
			<13344 13309 13288 13276 13269 13270>,
			<13350 13314 13292 13276 13269 13271>,
			<13356 13316 13294 13277 13269 13271>,
			<13361 13317 13295 13280 13271 13272>,
			<13366 13317 13297 13282 13272 13273>,
			<13373 13319 13299 13281 13275 13273>,
			<13380 13322 13301 13281 13278 13274>,
			<13386 13324 13304 13281 13279 13273>,
			<13389 13326 13307 13284 13280 13273>,
			<13392 13329 13309 13286 13280 13272>,
			<13395 13333 13311 13287 13277 13271>,
			<13397 13341 13313 13289 13274 13269>,
			<13400 13345 13313 13288 13273 13268>,
			<13404 13347 13311 13286 13273 13269>,
			<13412 13348 13309 13282 13274 13269>,
			<13425 13346 13304 13278 13272 13271>,
			<13451 13337 13299 13276 13270 13272>,
			<13632 13338 13303 13277 13270 13272>,
			<14416 13355 13309 13280 13271 13272>,
			<17025 13544 13323 13284 13278 13274>,
			<18669 13751 13345 13296 13282 13274>,
			<21463 14187 13384 13297 13283 13277>,
			<25002 14908 13461 13312 13283 13281>,
			<29486 15942 13579 13335 13297 13283>,
			<34521 17309 13756 13333 13287 13279>,
			<39466 18683 14016 13329 13289 13279>,
			<43567 20176 14433 13341 13294 13283>,
			<45231 21399 15094 13369 13304 13288>,
			<45231 21399 15094 13369 13304 13288>,
			<45231 21399 15094 13369 13304 13288>;
	};

	qcom,pc-temp-y4-lut {
		qcom,lut-col-legend = <(-10) 0 10 25 40 50>;
		qcom,lut-row-legend = <10000 9800 9600 9400 9200 9000>,
			<8800 8600 8400 8200 8000 7800>,
			<7600 7400 7200 7000 6800 6600>,
			<6400 6200 6000 5800 5600 5400>,
			<5200 5000 4800 4600 4400 4200>,
			<4000 3800 3600 3400 3200 3000>,
			<2800 2600 2400 2200 2000 1800>,
			<1600 1400 1200 1000 900 800>,
			<700 600 500 400 300 200>,
			<100 0>;
		qcom,lut-data = <16870 16635 16555 16512 16454 16446>,
			<16930 16667 16566 16502 16454 16445>,
			<16988 16699 16578 16498 16455 16444>,
			<17041 16730 16590 16498 16457 16445>,
			<17090 16758 16604 16501 16460 16447>,
			<17131 16780 16618 16505 16464 16448>,
			<17173 16797 16633 16514 16468 16451>,
			<17207 16811 16649 16526 16473 16454>,
			<17207 16830 16660 16537 16479 16457>,
			<17155 16855 16667 16549 16487 16460>,
			<17091 16882 16676 16560 16493 16463>,
			<17040 16909 16698 16568 16495 16470>,
			<16991 16939 16732 16576 16497 16479>,
			<16957 16973 16768 16593 16504 16487>,
			<16931 17022 16809 16628 16525 16492>,
			<16911 17053 16850 16657 16544 16500>,
			<16899 17017 16890 16673 16554 16516>,
			<16890 16922 16925 16687 16563 16538>,
			<16884 16838 16921 16712 16578 16554>,
			<16879 16754 16828 16747 16605 16568>,
			<16876 16695 16724 16762 16620 16575>,
			<16879 16683 16654 16700 16601 16559>,
			<16888 16676 16599 16606 16563 16530>,
			<16899 16675 16588 16560 16531 16504>,
			<16911 16683 16593 16529 16498 16476>,
			<16925 16696 16600 16519 16481 16463>,
			<16941 16709 16609 16525 16486 16466>,
			<16960 16724 16619 16536 16497 16473>,
			<16982 16742 16633 16544 16507 16481>,
			<17008 16765 16652 16552 16520 16492>,
			<17037 16792 16673 16562 16532 16504>,
			<17066 16818 16693 16575 16544 16517>,
			<17097 16846 16713 16591 16555 16530>,
			<17127 16875 16733 16604 16557 16534>,
			<17162 16907 16753 16617 16557 16537>,
			<17191 16940 16771 16627 16556 16538>,
			<17204 16973 16787 16634 16547 16524>,
			<17213 17007 16802 16638 16531 16502>,
			<17216 17020 16804 16628 16520 16493>,
			<17151 17005 16788 16597 16513 16490>,
			<17067 16973 16761 16577 16507 16486>,
			<17055 16912 16724 16570 16503 16477>,
			<17079 16807 16679 16565 16501 16471>,
			<17162 16799 16646 16559 16501 16473>,
			<17428 16847 16648 16548 16499 16473>,
			<18184 17031 16735 16567 16504 16479>,
			<18805 17102 16781 16586 16517 16491>,
			<20611 17283 16873 16632 16539 16503>,
			<23804 17511 16993 16667 16563 16510>,
			<28908 17970 17151 16687 16559 16511>,
			<36189 19047 17279 16700 16534 16478>,
			<46580 20587 17320 16669 16513 16476>,
			<62022 23163 17440 16695 16525 16490>,
			<65535 27910 17993 16737 16567 16530>,
			<65535 27910 17993 16737 16567 16530>,
			<65535 27910 17993 16737 16567 16530>;
	};

	qcom,pc-temp-y5-lut {
		qcom,lut-col-legend = <(-10) 0 10 25 40 50>;
		qcom,lut-row-legend = <10000 9800 9600 9400 9200 9000>,
			<8800 8600 8400 8200 8000 7800>,
			<7600 7400 7200 7000 6800 6600>,
			<6400 6200 6000 5800 5600 5400>,
			<5200 5000 4800 4600 4400 4200>,
			<4000 3800 3600 3400 3200 3000>,
			<2800 2600 2400 2200 2000 1800>,
			<1600 1400 1200 1000 900 800>,
			<700 600 500 400 300 200>,
			<100 0>;
		qcom,lut-data = <11094 12269 13232 9956 17711 18400>,
			<11185 12259 12954 11403 17162 18374>,
			<11273 12120 12687 12535 16609 18218>,
			<11356 11925 12433 13348 16070 17958>,
			<11432 11750 12196 13835 15564 17622>,
			<11500 11669 11977 13993 15111 17238>,
			<11549 11633 11737 13711 14707 16740>,
			<11597 11549 11535 13194 14323 16187>,
			<11831 11440 11525 12794 13914 15775>,
			<12933 11232 11686 12415 13434 15471>,
			<13919 11094 11800 12249 13195 15121>,
			<14293 11227 11732 12388 13582 14461>,
			<14583 11611 11615 12583 14182 13793>,
			<14567 12202 11602 12480 14125 13739>,
			<14122 13534 11731 11905 13219 14072>,
			<13602 14853 11969 11581 12630 14288>,
			<13217 15658 12969 11905 12799 13704>,
			<12879 16287 14693 12562 13165 12795>,
			<12734 16410 15756 13335 13528 12750>,
			<12688 16002 16473 14405 13924 13529>,
			<12648 15387 16825 15381 14441 14419>,
			<12568 14655 16051 16301 15513 15303>,
			<12466 13775 14481 16959 16669 16077>,
			<12418 13298 13640 16538 16604 16135>,
			<12436 13061 13133 14827 15105 15707>,
			<12493 12936 12856 13742 13859 15241>,
			<12635 13028 12971 13415 13401 14839>,
			<12917 13290 13270 13238 13112 14507>,
			<13168 13393 13412 13400 13096 14451>,
			<13387 13325 13429 13949 13282 14463>,
			<13615 13246 13450 14188 13561 14471>,
			<13878 13255 13544 13940 14082 14486>,
			<14213 13338 13728 13652 14746 14511>,
			<14516 13389 13901 13684 15171 14520>,
			<14761 13429 14064 13906 15530 14508>,
			<14993 13497 14177 14110 15695 14472>,
			<15260 13659 14219 14310 14994 14100>,
			<15561 14021 14243 14473 13901 13544>,
			<15761 14304 14228 14433 13711 13403>,
			<15878 14485 14091 14123 13825 13429>,
			<15951 14607 13892 13665 13899 13520>,
			<15037 14504 13507 12832 13383 14046>,
			<11904 13928 13068 12476 12856 14519>,
			<10945 12785 13178 12483 12864 14367>,
			<10633 11295 12807 12811 12989 14370>,
			<10151 10906 11492 12180 13425 13937>,
			<9798 10896 11359 12644 13508 13289>,
			<9459 10705 11170 11770 12812 13475>,
			<9246 10756 11280 12153 12282 13768>,
			<9153 10562 11120 12922 13805 13917>,
			<9109 10088 11010 12269 12978 14197>,
			<9032 9683 10986 11896 13941 14778>,
			<8953 9386 10862 11921 14518 16414>,
			<8898 9171 10319 12490 17030 17932>,
			<8898 9171 10319 12490 17030 17932>,
			<8898 9171 10319 12490 17030 17932>;
	};

	qcom,pc-temp-y6-lut {
		qcom,lut-col-legend = <(-10) 0 10 25 40 50>;
		qcom,lut-row-legend = <10000 9800 9600 9400 9200 9000>,
			<8800 8600 8400 8200 8000 7800>,
			<7600 7400 7200 7000 6800 6600>,
			<6400 6200 6000 5800 5600 5400>,
			<5200 5000 4800 4600 4400 4200>,
			<4000 3800 3600 3400 3200 3000>,
			<2800 2600 2400 2200 2000 1800>,
			<1600 1400 1200 1000 900 800>,
			<700 600 500 400 300 200>,
			<100 0>;
		qcom,lut-data = <5407 5184 5094 5033 5020 5018>,
			<5416 5191 5097 5036 5020 5017>,
			<5431 5198 5100 5039 5020 5017>,
			<5447 5205 5104 5043 5022 5017>,
			<5461 5212 5107 5046 5023 5019>,
			<5468 5217 5110 5050 5026 5020>,
			<5470 5221 5114 5054 5028 5022>,
			<5471 5224 5118 5058 5032 5025>,
			<5470 5226 5122 5062 5034 5027>,
			<5460 5227 5127 5065 5037 5029>,
			<5447 5228 5133 5069 5040 5031>,
			<5430 5235 5141 5074 5043 5034>,
			<5408 5247 5149 5080 5047 5036>,
			<5390 5262 5160 5085 5051 5040>,
			<5374 5285 5172 5091 5055 5043>,
			<5361 5301 5185 5098 5059 5047>,
			<5350 5289 5200 5107 5064 5051>,
			<5341 5259 5215 5119 5069 5054>,
			<5336 5231 5214 5128 5076 5060>,
			<5333 5203 5181 5138 5085 5067>,
			<5331 5181 5143 5142 5090 5072>,
			<5331 5171 5117 5117 5081 5065>,
			<5331 5163 5095 5081 5064 5051>,
			<5332 5161 5090 5062 5050 5040>,
			<5334 5162 5090 5049 5035 5029>,
			<5339 5164 5090 5045 5028 5023>,
			<5346 5168 5092 5046 5029 5024>,
			<5356 5175 5098 5049 5031 5027>,
			<5367 5183 5104 5052 5034 5029>,
			<5379 5190 5110 5056 5039 5033>,
			<5392 5198 5117 5061 5043 5037>,
			<5407 5208 5125 5064 5049 5042>,
			<5422 5218 5133 5068 5054 5046>,
			<5438 5229 5141 5073 5055 5046>,
			<5454 5242 5149 5079 5056 5047>,
			<5470 5255 5156 5083 5056 5047>,
			<5484 5270 5164 5086 5052 5042>,
			<5498 5288 5170 5089 5045 5034>,
			<5511 5297 5172 5086 5042 5032>,
			<5520 5298 5168 5076 5040 5031>,
			<5532 5298 5161 5068 5039 5031>,
			<5562 5292 5151 5065 5037 5030>,
			<5651 5275 5139 5063 5036 5029>,
			<5894 5287 5142 5064 5037 5030>,
			<6625 5370 5159 5067 5038 5031>,
			<8742 5664 5220 5080 5046 5035>,
			<10096 5884 5272 5097 5054 5040>,
			<12588 6290 5360 5116 5063 5047>,
			<15956 6881 5492 5143 5072 5053>,
			<20517 7772 5663 5173 5083 5055>,
			<26060 9100 5866 5184 5071 5044>,
			<32408 10531 6101 5182 5068 5045>,
			<39645 12334 6458 5210 5078 5053>,
			<47175 14576 7150 5258 5101 5070>,
			<47175 14576 7150 5258 5101 5070>,
			<47175 14576 7150 5258 5101 5070>;
	};

};
